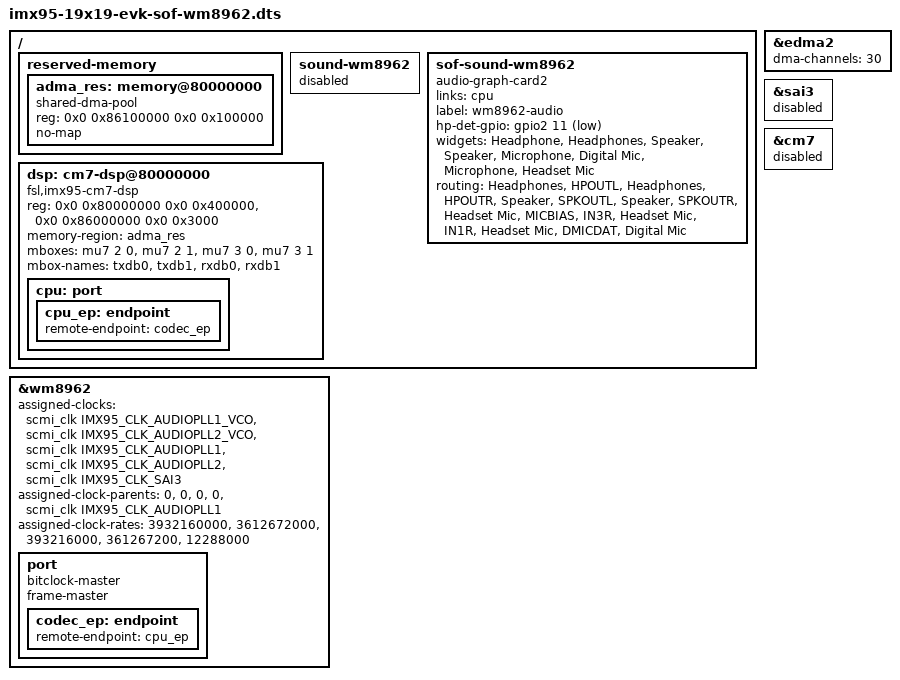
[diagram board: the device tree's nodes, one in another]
// SPDX-License-Identifier: (GPL-2.0+ OR MIT)
/*
 * Copyright 2024 NXP
 */

/dts-v1/;

#include "imx95-19x19-evk.dts"

/ {
	reserved-memory {
		adma_res: memory@80000000 {
			compatible = "shared-dma-pool";
			reg = <0x0 0x86100000 0x0 0x100000>;
			no-map;
		};
	};

	sound-wm8962 {
		status = "disabled";
	};

	sof-sound-wm8962 {
		compatible = "audio-graph-card2";
		links = <&cpu>;
		label = "wm8962-audio";
		hp-det-gpio = <&gpio2 11 GPIO_ACTIVE_LOW>;
		widgets =
			"Headphone", "Headphones",
			"Speaker", "Speaker",
			"Microphone", "Digital Mic",
			"Microphone", "Headset Mic";
		routing =
			"Headphones", "HPOUTL",
			"Headphones", "HPOUTR",
			"Speaker", "SPKOUTL",
			"Speaker", "SPKOUTR",
			"Headset Mic", "MICBIAS",
			"IN3R", "Headset Mic",
			"IN1R", "Headset Mic",
			"DMICDAT", "Digital Mic";
	};

	dsp: cm7-dsp@80000000 {
		compatible = "fsl,imx95-cm7-dsp";

		reg = <0x0 0x80000000 0x0 0x400000>,
		      <0x0 0x86000000 0x0 0x3000>;
		reg-names = "dram", "mailbox";

		memory-region = <&adma_res>;

		mboxes = <&mu7 2 0>, <&mu7 2 1>, <&mu7 3 0>, <&mu7 3 1>;
		mbox-names = "txdb0", "txdb1", "rxdb0", "rxdb1";

		cpu: port {
			cpu_ep: endpoint { remote-endpoint = <&codec_ep>; };
		};
	};
};

&wm8962 {
	assigned-clocks = <&scmi_clk IMX95_CLK_AUDIOPLL1_VCO>,
			  <&scmi_clk IMX95_CLK_AUDIOPLL2_VCO>,
			  <&scmi_clk IMX95_CLK_AUDIOPLL1>,
			  <&scmi_clk IMX95_CLK_AUDIOPLL2>,
			  <&scmi_clk IMX95_CLK_SAI3>;
	assigned-clock-parents = <0>, <0>, <0>, <0>, <&scmi_clk IMX95_CLK_AUDIOPLL1>;
	assigned-clock-rates = <3932160000>, <3612672000>,
			       <393216000>, <361267200>,
			       <12288000>;
	status = "okay";
	port {
		bitclock-master;
		frame-master;
		codec_ep: endpoint { remote-endpoint = <&cpu_ep>; };
	};
};

&edma2 {
	dma-channels = <30>;
};

&sai3 {
	status = "disabled";
};

&cm7 {
	status = "disabled";
};
